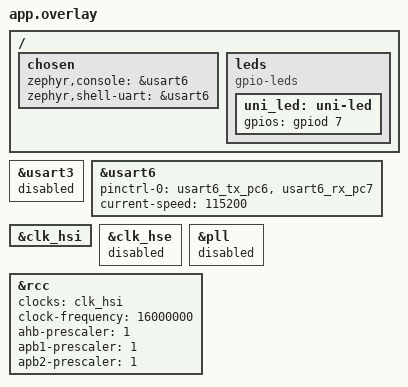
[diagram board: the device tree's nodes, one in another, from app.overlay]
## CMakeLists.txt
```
cmake_minimum_required(VERSION 3.20.0)
find_package(Zephyr REQUIRED HINTS $ENV{ZEPHYR_BASE})
project(uni_clicker_hello)
target_sources(app PRIVATE src/main.c)
```

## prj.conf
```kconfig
CONFIG_GPIO=y
CONFIG_SERIAL=y
CONFIG_BOOT_BANNER=n
CONFIG_DEBUG_OPTIMIZATIONS=y
```

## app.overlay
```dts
#include <zephyr/dt-bindings/gpio/gpio.h>

/ {
    chosen {
        zephyr,console = &usart6;
        zephyr,shell-uart = &usart6;
    };

    leds {
        compatible = "gpio-leds";

        uni_led: uni-led {
            gpios = <&gpiod 7 GPIO_ACTIVE_HIGH>;
        };
    };
};

&usart3 {
    status = "disabled";
};

&usart6 {
    pinctrl-0 = <&usart6_tx_pc6 &usart6_rx_pc7>;
    pinctrl-names = "default";
    current-speed = <115200>;
    status = "okay";
};

&clk_hsi {
    status = "okay";
};

&clk_hse {
    status = "disabled";
};

&pll {
    status = "disabled";
};

&rcc {
    clocks = <&clk_hsi>;
    clock-frequency = <16000000>;
    ahb-prescaler = <1>;
    apb1-prescaler = <1>;
    apb2-prescaler = <1>;
};
```

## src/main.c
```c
#include <zephyr/device.h>
#include <zephyr/drivers/gpio.h>
#include <zephyr/drivers/uart.h>
#include <zephyr/kernel.h>

static const struct gpio_dt_spec led = GPIO_DT_SPEC_GET(DT_NODELABEL(uni_led), gpios);
static const struct device *const uart = DEVICE_DT_GET(DT_CHOSEN(zephyr_console));
volatile uint32_t uni_heartbeat;
volatile uint32_t uni_tx_bytes;

static void write_banner(void)
{
    static const char banner[] = "Hello, UNI Clicker from Zephyr!\r\n";

    for (size_t i = 0; i < sizeof(banner) - 1; ++i) {
        uart_poll_out(uart, banner[i]);
    }
    uni_tx_bytes += sizeof(banner) - 1;
}

int main(void)
{
    if (!device_is_ready(uart) || !gpio_is_ready_dt(&led) ||
        gpio_pin_configure_dt(&led, GPIO_OUTPUT_INACTIVE) != 0) {
        return 1;
    }

    write_banner();
    for (;;) {
        k_msleep(500);
        gpio_pin_set_dt(&led, 1);
        ++uni_heartbeat;
        k_msleep(500);
        gpio_pin_set_dt(&led, 0);
        ++uni_heartbeat;
        write_banner();
    }
}
```
